VERSION ""

NS_ :

BS_:

BU_: Batteriemanagement Bordnetzmanagement Energieversorgung System

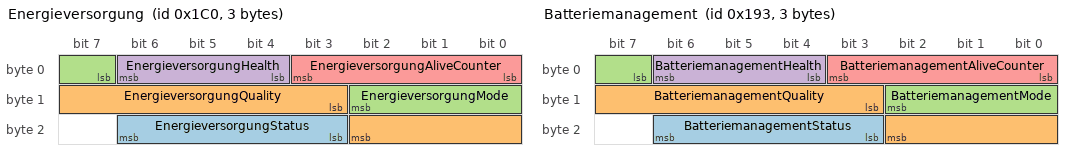
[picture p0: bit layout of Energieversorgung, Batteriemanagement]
BO_ 448 Energieversorgung: 3 Energieversorgung
 SG_ EnergieversorgungStatus : 19|4@1+ (1,0) [0.0|15.0] "code"  System
 SG_ EnergieversorgungQuality : 11|8@1+ (0.5,0.0) [0.0|100.0] "%"  System
 SG_ EnergieversorgungMode : 7|4@1+ (1,0) [0.0|15.0] "code"  System
 SG_ EnergieversorgungHealth : 4|3@1+ (1,0) [0.0|7.0] "code"  System
 SG_ EnergieversorgungAliveCounter : 0|4@1+ (1,0) [0.0|15.0] "count"  System

BO_ 403 Batteriemanagement: 3 Batteriemanagement
 SG_ BatteriemanagementStatus : 19|4@1+ (1,0) [0.0|15.0] "code"  System
 SG_ BatteriemanagementQuality : 11|8@1+ (0.5,0.0) [0.0|100.0] "%"  System
 SG_ BatteriemanagementMode : 7|4@1+ (1,0) [0.0|15.0] "code"  System
 SG_ BatteriemanagementHealth : 4|3@1+ (1,0) [0.0|7.0] "code"  System
 SG_ BatteriemanagementAliveCounter : 0|4@1+ (1,0) [0.0|15.0] "count"  System

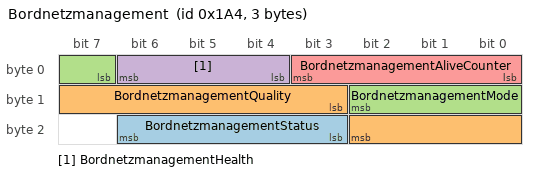
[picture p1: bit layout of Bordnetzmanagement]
BO_ 420 Bordnetzmanagement: 3 Bordnetzmanagement
 SG_ BordnetzmanagementStatus : 19|4@1+ (1,0) [0.0|15.0] "code"  System
 SG_ BordnetzmanagementQuality : 11|8@1+ (0.5,0.0) [0.0|100.0] "%"  System
 SG_ BordnetzmanagementMode : 7|4@1+ (1,0) [0.0|15.0] "code"  System
 SG_ BordnetzmanagementHealth : 4|3@1+ (1,0) [0.0|7.0] "code"  System
 SG_ BordnetzmanagementAliveCounter : 0|4@1+ (1,0) [0.0|15.0] "count"  System

CM_ BO_ 448 "CanonicalMessage=60b6e943-d485-4078-8ef4-aaab78e8b13d; Network=Energieversorgung_02-S01; Technology=can_fd";
CM_ SG_ 448 EnergieversorgungStatus "CanonicalSignal=0ed761df-ffd6-4a54-a435-5e15def88ffd";
CM_ SG_ 448 EnergieversorgungQuality "CanonicalSignal=2cab4874-3734-4bca-a8a9-c5cabc15b60d";
CM_ SG_ 448 EnergieversorgungMode "CanonicalSignal=64b056db-c6e6-42b1-9ec0-5889ecf018fa";
CM_ SG_ 448 EnergieversorgungHealth "CanonicalSignal=c7b21a0b-3791-4ec9-8c35-c77efad53d0b";
CM_ SG_ 448 EnergieversorgungAliveCounter "CanonicalSignal=f42786cb-743b-45ee-8bd5-0085fffc97bd";
CM_ BO_ 403 "CanonicalMessage=3c795b7a-08d9-4417-88dc-847b9ed98665; Network=Energieversorgung_02-S01; Technology=can_fd";
CM_ SG_ 403 BatteriemanagementStatus "CanonicalSignal=ed40c0dc-91ca-46fc-a7a7-b0e55e94bd1c";
CM_ SG_ 403 BatteriemanagementQuality "CanonicalSignal=975362ea-dff6-4c0b-84b5-e05552c40604";
CM_ SG_ 403 BatteriemanagementMode "CanonicalSignal=ae422fe3-89ad-4030-9c42-9344765a501b";
CM_ SG_ 403 BatteriemanagementHealth "CanonicalSignal=3a83335f-324b-4610-9a08-f98cbcf98302";
CM_ SG_ 403 BatteriemanagementAliveCounter "CanonicalSignal=19bbb27e-adad-4a0c-a329-7aa64483b58b";
CM_ BO_ 420 "CanonicalMessage=05af4069-3699-47be-880e-7f67e19292cd; Network=Energieversorgung_02-S01; Technology=can_fd";
CM_ SG_ 420 BordnetzmanagementStatus "CanonicalSignal=a5a96d90-5c12-45d9-ad62-7884e4197c3e";
CM_ SG_ 420 BordnetzmanagementQuality "CanonicalSignal=6d2fd496-79e3-4f64-bc02-11a17e9bb795";
CM_ SG_ 420 BordnetzmanagementMode "CanonicalSignal=34ad3673-4393-44e1-a6ba-ccfb4276c771";
CM_ SG_ 420 BordnetzmanagementHealth "CanonicalSignal=45e18b5e-95c3-4faa-a849-35b33a9f9efb";
CM_ SG_ 420 BordnetzmanagementAliveCounter "CanonicalSignal=bc2b1282-71a1-470e-892e-83479e8d490d";
BA_DEF_ BO_  "VFrameFormat" ENUM  "StandardCAN","ExtendedCAN","StandardCAN_FD","ExtendedCAN_FD";
BA_DEF_DEF_  "VFrameFormat" "0";
BA_ "VFrameFormat" BO_ 448 2;
BA_ "VFrameFormat" BO_ 403 2;
BA_ "VFrameFormat" BO_ 420 2;
